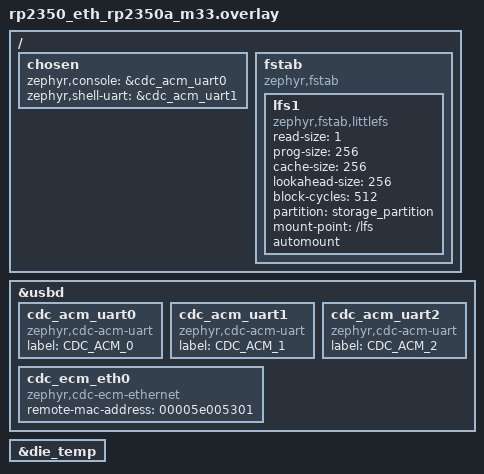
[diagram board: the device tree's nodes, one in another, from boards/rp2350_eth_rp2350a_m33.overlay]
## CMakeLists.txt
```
# SPDX-License-Identifier: Apache-2.0

cmake_minimum_required(VERSION 3.20.0)
find_package(Zephyr REQUIRED HINTS $ENV{ZEPHYR_BASE})
project(shell_module)

zephyr_library_sources(src/main.cpp)
zephyr_library_sources_ifdef(CONFIG_APP_BLINKY src/led.c)
zephyr_library_sources_ifdef(CONFIG_APP_SCPI src/scpi.cpp)
zephyr_library_sources_ifdef(CONFIG_SETTINGS src/settings.c)
zephyr_library_sources_ifdef(CONFIG_APP_ECHO_SERVER src/console_server.c)
target_sources(app PRIVATE ${app_sources}) # ${scpi_sources})

target_compile_options(
		app
		PRIVATE -Wall # All common warnings
										-Wextra # Extra warnings
										-Wpedantic # Strict ISO compliance
										-Wconversion # Implicit conversions
										-Wshadow # Variable shadowing
										-Wnon-virtual-dtor # Warn if class has virtual methods but no virtual
										# destructor
		# -Wold-style-cast   # Old-style casts (C-style)
)
```

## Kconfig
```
# Copyright (c) 2019 Nordic Semiconductor ASA
# SPDX-License-Identifier: Apache-2.0

menu "Application Configuration"
config APP_ECHO_SERVER
	bool "Enable echo telnet server"
	default n 
	help 
		Enable echo server 
	depends on NETWORKING
	depends on NET_TCP
	depends on NET_IPV4 || NET_IPV6
	select NET_SOCKETS_SERVICE
	select NET_SOCKETS

config APP_BLINKY
	bool "Enable blinky"
	select LED_STRIP
	default n
	help 
	  Use led strip blinky

if APP_BLINKY
config SAMPLE_LED_UPDATE_DELAY
	int "Delay between LED updates in ms"
	default 50
	help
	  Delay between LED updates in ms.

config SAMPLE_LED_BRIGHTNESS
	int "LED brightness"
	default 12
	range 1 255
	help
	  Brightness level of each LED. Defaults to a low value to make
	  it easier to distinguish colors.

endif

config APP_RS485 
	bool "Half duplex RS-485 serial"
	select UART_LINE_CTRL
	default n
	help 
		Enable flow control for RS-485 half duplex

config APP_SCPI
	bool "Enable SCPI Console"
	depends on CONSOLE
	depends on CONSOLE_SUBSYS
	depends on UART_CONSOLE
	depends on CONSOLE_GETCHAR
	depends on !CONSOLE_GETLINE
	default n
	help 
	  Enable scpi over console

config APP_FULL_BINDESC
	bool "Enable full bin description fields"
	select BINDESC
	select BINDESC_DEFINE
	select BINDESC_DEFINE_BUILD_TIME
	select BINDESC_BUILD_DATE_TIME_STRING
	select BINDESC_BUILD_TIME_ALWAYS_REBUILD
	select BINDESC_DEFINE_VERSION
	select BINDESC_KERNEL_VERSION_STRING
	select BINDESC_DEFINE_HOST_INFO
	select BINDESC_APP_VERSION_STRING
	select BINDESC_APP_VERSION_MAJOR
	select BINDESC_APP_VERSION_MINOR
	select BINDESC_APP_VERSION_PATCHLEVEL
	select BINDESC_APP_VERSION_NUMBER
	select BINDESC_APP_BUILD_VERSION
	select BINDESC_DEFINE_HOST_INFO
	select BINDESC_HOST_NAME
	select BINDESC_C_COMPILER_NAME
	select BINDESC_C_COMPILER_VERSION
	select BINDESC_CXX_COMPILER_NAME
	select BINDESC_CXX_COMPILER_VERSION
	default y 
	help 
		Selects all default bindesc fields 
		
endmenu

source "Kconfig.zephyr"
```

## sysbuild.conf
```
# Sysbuild configuration file.

# Enable MCUboot using overwrite only mode for this sample.
#SB_CONFIG_BOOTLOADER_NONE=y
SB_CONFIG_BOOTLOADER_MCUBOOT=y

#SB_CONFIG_MCUBOOT_SIGNATURE_KEY_FILE="bootloader/mcuboot/root-rsa-2048.pem"

SB_CONFIG_BOOT_SIGNATURE_TYPE_NONE=y
SB_CONFIG_MCUBOOT_MODE_SWAP_SCRATCH=n
SB_CONFIG_MCUBOOT_MODE_SWAP_USING_MOVE=y
SB_CONFIG_MCUBOOT_MODE_OVERWRITE_ONLY=n 
SB_CONFIG_MCUBOOT_MODE_DIRECT_XIP=n 
SB_CONFIG_MCUBOOT_MODE_DIRECT_XIP_WITH_REVERT=n 
SB_CONFIG_MCUBOOT_MODE_FIRMWARE_UPDATER=n 
SB_CONFIG_MCUBOOT_MODE_SINGLE_APP=n

# SB_CONFIG_MCUBOOT_MODE_RAM_LOAD=y
```

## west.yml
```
manifest:
  version: 0.8

  projects:
    - name: zephyr
      url: https://github.com/zephyrproject-rtos/zephyr
      revision: v4.3.0
      import:
        file: west.yml
        path-prefix: deps
        name-allowlist:
          - zephyr
          - cmsis
          - cmsis_6
          - hal_nordic
          - mcuboot
          - zcbor
          - mbedtls
          - modbus
          - hal_rpi_pico
          - littlefs
          - picolibc

    - name: scpi-parser
      url: https://github.com/snhobbs/scpi-parser
      revision: master # or a specific tag/commit
      path: deps/scpi-parser # local folder inside your Zephyr workspace

  self:
    path: app
```

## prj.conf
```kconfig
confs/prj.conf
```

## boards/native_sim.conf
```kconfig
CONFIG_STDOUT_CONSOLE=n
CONFIG_GLIBCXX_LIBCPP=n

# CONFIG_COMMON_LIBC_REMOVE=n
# CONFIG_EXTERNAL_MODULE_LIBCPP is not set
# CONFIG_CPP_EXCEPTIONS is not set
# CONFIG_CPP_RTTI is not set
#

# CONFIG_FUSE_FS_ACCESS=y

CONFIG_SYMTAB=n


CONFIG_SYMTAB_SHELL=n
CONFIG_ISR_TABLE_SHELL=n
CONFIG_PICOLIBC=n
CONFIG_MINIMAL_LIBC=n
```

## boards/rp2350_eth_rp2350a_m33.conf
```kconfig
CONFIG_APP_BLINKY=y
```

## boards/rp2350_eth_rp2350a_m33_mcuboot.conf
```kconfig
CONFIG_APP_BLINKY=y
CONFIG_SAMPLE_LED_UPDATE_DELAY=25
CONFIG_SAMPLE_LED_BRIGHTNESS=2

##################################
# MCUBOOT
##################################
CONFIG_IMG_MANAGER=y
CONFIG_IMG_ENABLE_IMAGE_CHECK=y 
CONFIG_MCUBOOT_IMG_MANAGER=y

CONFIG_MCUBOOT_SHELL=y
CONFIG_UPDATEABLE_IMAGE_NUMBER=1
CONFIG_BOOTLOADER_MCUBOOT=y
CONFIG_MCUBOOT_BOOTUTIL_LIB=y

CONFIG_FLASH=y
CONFIG_FLASH_MAP=y
CONFIG_STREAM_FLASH=y

CONFIG_RETENTION=y
CONFIG_RETENTION_BOOT_MODE=y
CONFIG_RETAINED_MEM=y
CONFIG_REBOOT=y
CONFIG_RESET=y

##################################
# MCUMGR 
##################################
CONFIG_NET_BUF=y
CONFIG_BASE64=y
CONFIG_ZCBOR=y
CONFIG_CRC=y

CONFIG_SHELL=y

CONFIG_FLASH=y
CONFIG_FLASH_MAP=y
CONFIG_STREAM_FLASH=y
CONFIG_STREAM_FLASH_PROGRESS=n
CONFIG_STREAM_FLASH_INSPECT=y
CONFIG_STREAM_FLASH_ERASE=y

# mcumgr core
CONFIG_MCUMGR=y
CONFIG_MCUMGR_GRP_SHELL=y
CONFIG_MCUMGR_TRANSPORT_SHELL=y
# CONFIG_MCUMGR_TRANSPORT_UART=y
# CONFIG_UART_MCUMGR=y
CONFIG_SHELL_BACKEND_DUMMY=y
CONFIG_MCUMGR_LOG_LEVEL_DBG=y

CONFIG_MCUMGR_GRP_IMG=y
CONFIG_MCUMGR_GRP_IMG_UPDATABLE_IMAGE_NUMBER=1
CONFIG_MCUMGR_GRP_IMG_VERBOSE_ERR=y
CONFIG_MCUMGR_GRP_IMG_ALLOW_CONFIRM_NON_ACTIVE_IMAGE_SECONDARY=y
CONFIG_MCUMGR_GRP_IMG_ALLOW_CONFIRM_NON_ACTIVE_IMAGE_ANY=y
CONFIG_MCUMGR_GRP_IMG_ALLOW_ERASE_PENDING=y
CONFIG_MCUMGR_GRP_IMG_DIRECT_UPLOAD=y
CONFIG_MCUMGR_GRP_IMG_ALLOW_CONFIRM_NON_ACTIVE_SLOT=y
# CONFIG_MCUMGR_GRP_IMG_FRUGAL_LIST is not set
CONFIG_MCUMGR_GRP_IMG_VERSION_CMP_USE_BUILD_NUMBER=y
# CONFIG_MCUMGR_GRP_IMG_MUTEX is not set
# CONFIG_MCUMGR_GRP_IMG_TOO_LARGE_DISABLED is not set
CONFIG_MCUMGR_GRP_IMG_TOO_LARGE_SYSBUILD=y
CONFIG_MCUMGR_GRP_IMG_IMAGE_SLOT_STATE_STATES=15
CONFIG_MCUMGR_GRP_IMG_SLOT_INFO=y

CONFIG_MCUMGR_GRP_OS=y
CONFIG_MCUMGR_GRP_OS_RESET_MS=250
# CONFIG_MCUMGR_GRP_OS_TASKSTAT is not set
CONFIG_MCUMGR_GRP_OS_ECHO=y
CONFIG_MCUMGR_GRP_OS_MCUMGR_PARAMS=y
CONFIG_MCUMGR_GRP_OS_INFO=y
CONFIG_MCUMGR_GRP_OS_INFO_BUILD_DATE_TIME=y
CONFIG_MCUMGR_GRP_OS_BOOTLOADER_INFO=y

CONFIG_MCUMGR_GRP_STAT=y
CONFIG_MCUMGR_GRP_ZBASIC=y
CONFIG_MCUMGR_GRP_ZBASIC_STORAGE_ERASE=y
CONFIG_MCUMGR_GRP_SETTINGS=y
CONFIG_MCUMGR_GRP_ENUM=y
```

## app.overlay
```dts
/*
 * Copyright (c) 2021 Nordic Semiconductor ASA
 *
 * SPDX-License-Identifier: Apache-2.0
 */

//#include <zephyr/dt-bindings/dma/rpi-pico-dma-rp2040.h>
//#include <zephyr/dt-bindings/dma/rpi-pico-dma-rp2350.h>
//#include <zephyr/dt-bindings/pinctrl/rpi-pico-rp2350a-pinctrl.h>

/ {
	chosen {
		zephyr,mcumgr = &cdc_acm_uart0;
		zephyr,shell-uart = &cdc_acm_uart1;
		zephyr,console = &cdc_acm_uart2;
		//zephyr,code-partition = &slot0_partition;
	};
};

&die_temp {
	status = "okay";
};



&zephyr_udc0 {
	cdc_acm_uart0: cdc_acm_uart0 {
		status = "okay";
		compatible = "zephyr,cdc-acm-uart";
		label = "CDC_ACM_0";
	};
	cdc_acm_uart1: cdc_acm_uart1 {
		status = "okay";
		compatible = "zephyr,cdc-acm-uart";
		label = "CDC_ACM_1";
	};
	cdc_acm_uart2: cdc_acm_uart2 {
		status = "okay";
		compatible = "zephyr,cdc-acm-uart";
		label = "CDC_ACM_2";
	};
};
```

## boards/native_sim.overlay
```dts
/*
 * Copyright (c) 2019 Jan Van Winkel (jan.van_winkel@dxplore.eu)
 *
 * SPDX-License-Identifier: Apache-2.0
 */

/ {
	chosen {
		zephyr,uart-mcumgr = &uart0;
		zephyr,shell-uart = &uart1;
		zephyr,console = &uart2;
	};

	uart0: uart {
		status = "okay";
		compatible = "zephyr,native-pty-uart";
		/* Dummy current-speed entry to comply with serial
		 * DTS binding
		 */
		current-speed = <115200>;
	};

	uart1: uart_1 {
		status = "okay";
		compatible = "zephyr,native-pty-uart";
		/* Dummy current-speed entry to comply with serial
		 * DTS binding
		 */
		current-speed = <0>;
	};
	uart2: uart_2 {
		status = "okay";
		compatible = "zephyr,native-pty-uart";
		/* Dummy current-speed entry to comply with serial
		 * DTS binding
		 */
		current-speed = <0>;
	};
};


/ {
	fstab {
		compatible = "zephyr,fstab";
		lfs1: lfs1 {
			compatible = "zephyr,fstab,littlefs";
			read-size = <1>;
			prog-size = <256>;
			cache-size = <256>;
			lookahead-size = <256>;
			block-cycles = <512>;
			partition = <&storage_partition>;
			mount-point = "/lfs";
			automount;
		};
	};
};
```

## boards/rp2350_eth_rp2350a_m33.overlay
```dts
#include <vendor/raspberrypi/rp2350-boot-mode-retention.dtsi>
/ {
	chosen {
		zephyr,console = &cdc_acm_uart0;
		zephyr,shell-uart = &cdc_acm_uart1;
		//zephyr,uart-mcumgr = &cdc_acm_uart2;
	};
};

zephyr_udc0: &usbd {
	//compatible = "raspberrypi,rp-usbd";
	status = "okay";
	cdc_acm_uart0: cdc_acm_uart0 {
		status = "okay";
		compatible = "zephyr,cdc-acm-uart";
		label = "CDC_ACM_0";
	};
	cdc_acm_uart1: cdc_acm_uart1 {
		status = "okay";
		compatible = "zephyr,cdc-acm-uart";
		label = "CDC_ACM_1";
	};
	cdc_acm_uart2: cdc_acm_uart2 {
		status = "okay";
		compatible = "zephyr,cdc-acm-uart";
		label = "CDC_ACM_2";
	};
	cdc_ecm_eth0: cdc_ecm_eth0 {
		compatible = "zephyr,cdc-ecm-ethernet";
		remote-mac-address = "00005e005301";
	};
};

&die_temp {
	status = "okay";
};

/ {
	fstab {
		compatible = "zephyr,fstab";
		lfs1: lfs1 {
			compatible = "zephyr,fstab,littlefs";
			read-size = <1>;
			prog-size = <256>;
			cache-size = <256>;
			lookahead-size = <256>;
			block-cycles = <512>;
			partition = <&storage_partition>;
			mount-point = "/lfs";
			automount;
		};
	};
};
```

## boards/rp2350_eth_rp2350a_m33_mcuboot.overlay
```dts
#include <vendor/raspberrypi/rp2350-boot-mode-retention.dtsi>

/ {
	chosen {
		zephyr,console = &cdc_acm_uart0;
		zephyr,shell-uart = &cdc_acm_uart1;
		zephyr,uart-mcumgr = &cdc_acm_uart2;
		zephyr,code-partition = &slot0_partition;
	};
};

zephyr_udc0: &usbd {
	//compatible = "raspberrypi,rp-usbd";
	status = "okay";
	cdc_acm_uart0: cdc_acm_uart0 {
		status = "okay";
		compatible = "zephyr,cdc-acm-uart";
		label = "CDC_ACM_0";
	};
	cdc_acm_uart1: cdc_acm_uart1 {
		status = "okay";
		compatible = "zephyr,cdc-acm-uart";
		label = "CDC_ACM_1";
	};
	cdc_acm_uart2: cdc_acm_uart2 {
		status = "okay";
		compatible = "zephyr,cdc-acm-uart";
		label = "CDC_ACM_2";
	};
};
```

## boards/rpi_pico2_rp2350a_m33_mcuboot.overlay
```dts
/ {
	chosen {
		zephyr,shell-uart = &cdc_acm_uart1;
		zephyr,console = &cdc_acm_uart2;
		zephyr,code-partition = &slot0_partition;
	};
};

zephyr_udc0: &usbd {
	//compatible = "raspberrypi,rp-usbd";
	status = "okay";
	cdc_acm_uart0: cdc_acm_uart0 {
		status = "okay";
		compatible = "zephyr,cdc-acm-uart";
		label = "CDC_ACM_0";
	};
	cdc_acm_uart1: cdc_acm_uart1 {
		status = "okay";
		compatible = "zephyr,cdc-acm-uart";
		label = "CDC_ACM_1";
	};
	cdc_acm_uart2: cdc_acm_uart2 {
		status = "okay";
		compatible = "zephyr,cdc-acm-uart";
		label = "CDC_ACM_2";
	};

};
```

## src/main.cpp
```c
/*
 * Copyright (c) 2016 Intel Corporation.
 *
 * SPDX-License-Identifier: Apache-2.0
 */

#include <zephyr/bindesc.h>

#include <zephyr/app_version.h>
#include <zephyr/console/console.h>
#include <zephyr/console/tty.h>
#include <zephyr/devicetree.h>
#include <zephyr/drivers/uart.h>
#include <zephyr/dsp/print_format.h>
#include <zephyr/kernel.h>
#include <zephyr/rtio/rtio.h>
#include <zephyr/sys/printk.h>
#include <zephyr/sys/util_macro.h>

#include <zephyr/device.h>
#include <zephyr/logging/log.h>

#include <zephyr/device.h>
#include <zephyr/drivers/gpio.h>
#include <zephyr/kernel.h>

#define WORKQ_STACK_SIZE 1024
#define WORKQ_PRIORITY K_LOWEST_APPLICATION_THREAD_PRIO

K_THREAD_STACK_DEFINE(workq_stack, WORKQ_STACK_SIZE);
static struct k_work_q workq;
#if CONFIG_APP_BLINKY
#include "led.h"
K_WORK_DEFINE(led_work, led_work_handler);

void led_timer_handler(struct k_timer *timer_id) {
  k_work_submit_to_queue(&workq, &led_work);
}

K_TIMER_DEFINE(timer, led_timer_handler, NULL);

void start_led_timer() {
  k_timer_start(&timer, K_MSEC(0), K_MSEC(CONFIG_SAMPLE_LED_UPDATE_DELAY));
}

#else
void setup_leds() {}
void led_work_handler(struct k_work *work) {}
#endif

#if CONFIG_SETTINGS
#include "settings.h"
#endif

#if CONFIG_APP_SCPI
#include "scpi.hpp"
#include <array>
#include <scpi/scpi.h>
#endif

#if CONFIG_NETWORKING
#include "console_server.h"
#endif

#define BINDESC_ID_APP_VERSION_STRING APP_VERSION

// BUILD_ASSERT(DT_NODE_HAS_COMPAT(DT_CHOSEN(zephyr_console),
// zephyr_cdc_acm_uart),
//              "Console device is not ACM CDC UART device");

/* Declare the timer */
#define LOG_LEVEL 4
#include <zephyr/logging/log.h>
LOG_MODULE_REGISTER(main);

#if CONFIG_BOOT_SERIAL_BOOT_MODE
#include <zephyr/retention/bootmode.h>
#include <zephyr/shell/shell.h>
#include <zephyr/sys/reboot.h>
static int cmd_mcuboot_serial(const struct shell *sh, size_t argc,
                              char **argv) {

  shell_print(sh, "\n");
  int rc = bootmode_set(BOOT_MODE_TYPE_BOOTLOADER);

  if (rc == 0)
    sys_reboot(SYS_REBOOT_WARM);

  return 0;
}

SHELL_CMD_REGISTER(serial_recovery, NULL, "Serial recovery",
                   cmd_mcuboot_serial);
#endif

int main(void) {
#if CONFIG_APP_BLINKY
  k_work_queue_start(&workq, workq_stack, K_THREAD_STACK_SIZEOF(workq_stack),
                     WORKQ_PRIORITY, NULL);
  start_led_timer();
#endif

#if CONFIG_APP_SCPI
  console_init();
  start_scpi_thread();
#endif

#if CONFIG_SETTINGS
  const int retval = app_settings_init();
#endif

#if APP_ECHO_SERVER
  run_server();
#endif
  return 0;
}
```

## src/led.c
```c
#include "led.h"
#include <errno.h>
#include <string.h>

#include <zephyr/device.h>
#include <zephyr/drivers/led_strip.h>
#include <zephyr/kernel.h>
#include <zephyr/sys/util.h>

#define LOG_LEVEL 4
#include <zephyr/logging/log.h>
LOG_MODULE_REGISTER(led);

#define STRIP_NODE DT_ALIAS(led_strip)

#if DT_NODE_HAS_PROP(STRIP_NODE, chain_length)
#define STRIP_NUM_PIXELS DT_PROP(STRIP_NODE, chain_length)
#else
#error Unable to determine length of LED strip
#endif

#define RGB(_r, _g, _b) {.r = (_r), .g = (_g), .b = (_b)}

static const struct led_rgb colors[] = {
    RGB(CONFIG_SAMPLE_LED_BRIGHTNESS, 0x00, 0x00), /* red */
    RGB(0x00, CONFIG_SAMPLE_LED_BRIGHTNESS, 0x00), /* green */
    RGB(0x00, 0x00, CONFIG_SAMPLE_LED_BRIGHTNESS), /* blue */
};

static struct led_rgb pixels[STRIP_NUM_PIXELS];

static const struct device *const strip = DEVICE_DT_GET(STRIP_NODE);

static size_t color = 0;

void setup_leds(void) {
  if (device_is_ready(strip)) {
    LOG_INF("Found LED strip device %s", strip->name);
  } else {
    LOG_ERR("LED strip device %s is not ready", strip->name);
  }
}

void led_work_handler(struct k_work *work) {
  ARG_UNUSED(work);
  for (size_t cursor = 0; cursor < ARRAY_SIZE(pixels); cursor++) {
    memset(&pixels, 0x00, sizeof(pixels));
    memcpy(&pixels[cursor], &colors[color], sizeof(struct led_rgb));

    const int rc = led_strip_update_rgb(strip, pixels, STRIP_NUM_PIXELS);
    if (rc) {
      LOG_ERR("couldn't update strip: %u", rc);
    }
  }

  color = (color + 1) % ARRAY_SIZE(colors);
}
```

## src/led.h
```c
#include <zephyr/kernel.h>

#ifdef __cplusplus
extern "C" {
#endif
extern void setup_leds();
extern void led_work_handler(struct k_work *work);

#ifdef __cplusplus
};
#endif
```

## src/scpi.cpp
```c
/*
 * Copyright (c) 2025 ElectroOptical Innovations. All Rights Reserved.
 * scpi.cpp
 * Structure
 * + Forward declarations
 * + Table
 * + Functions
 * */

#include "scpi.hpp"
#include <array>
#include <cstdio>
#include <iostream>
#include <limits>
#include <scpi/scpi.h>
#include <span>

static scpi_result_t SCPI_Help(scpi_t *context);

// shell_put_line(g_serial_number.data());
// shell_put_line(compile_date);
// reset();

// ---- Helper Macros ----
#define SCPI_DEF_SETTER(name, setter)                                          \
  static void setter(uint32_t) {}                                              \
  static scpi_result_t SCPI_Set_##name(scpi_t *context) {                      \
    uint32_t value;                                                            \
    if (!SCPI_ParamUInt32(context, &value, true)) {                            \
      return SCPI_RES_ERR;                                                     \
    }                                                                          \
    setter(value);                                                             \
    return SCPI_RES_OK;                                                        \
  }

#define SCPI_DEF_GETTER(name, getter)                                          \
  static uint32_t getter() { return 0; }                                       \
  static scpi_result_t SCPI_Get_##name(scpi_t *context) {                      \
    SCPI_ResultUInt32(context, getter());                                      \
    return SCPI_RES_OK;                                                        \
  }

#define SCPI_DEF_BOOL_SETTER(name, setter)                                     \
  static void setter(bool) {}                                                  \
  static scpi_result_t SCPI_Set_##name(scpi_t *context) {                      \
    bool value;                                                                \
    if (!SCPI_ParamBool(context, &value, true)) {                              \
      return SCPI_RES_ERR;                                                     \
    }                                                                          \
    setter(value);                                                             \
    return SCPI_RES_OK;                                                        \
  }

#define SCPI_DEF_BOOL_GETTER(name, getter)                                     \
  static bool getter() { return false; }                                       \
  static scpi_result_t SCPI_Get_##name(scpi_t *context) {                      \
    SCPI_ResultBool(context, getter());                                        \
    return SCPI_RES_OK;                                                        \
  }

// ---- Concrete bindings ----
SCPI_DEF_SETTER(Vbtx, set_txdac)
SCPI_DEF_GETTER(Vbtx, get_txdac)

SCPI_DEF_SETTER(Vbrx, set_rxdac)
SCPI_DEF_GETTER(Vbrx, get_rxdac)

SCPI_DEF_SETTER(Slbias, set_slbias)
SCPI_DEF_GETTER(Slbias, get_slbias)

SCPI_DEF_SETTER(Sbbias, set_sbbias)
SCPI_DEF_GETTER(Sbbias, get_sbbias)

SCPI_DEF_SETTER(Da, set_da)
SCPI_DEF_GETTER(Da, get_da)

SCPI_DEF_SETTER(Db, set_db)
SCPI_DEF_GETTER(Db, get_db)

SCPI_DEF_BOOL_SETTER(vtdr_enable, set_vtdr_enable);
SCPI_DEF_BOOL_GETTER(vtdr_enable, get_vtdr_enable);

SCPI_DEF_BOOL_SETTER(v3p6r_enable, set_v3p6r_enable);
SCPI_DEF_BOOL_GETTER(v3p6r_enable, get_v3p6r_enable);

SCPI_DEF_SETTER(npoints, set_npoints);
SCPI_DEF_GETTER(npoints, get_npoints);

SCPI_DEF_SETTER(naverages, set_naverages);
SCPI_DEF_GETTER(naverages, get_naverages);

SCPI_DEF_SETTER(istart, set_istart);
SCPI_DEF_GETTER(istart, get_istart);

SCPI_DEF_SETTER(npulses, set_npulses);
SCPI_DEF_GETTER(npulses, get_npulses);

SCPI_DEF_SETTER(a, set_a);
SCPI_DEF_GETTER(a, get_a);

SCPI_DEF_SETTER(rc, set_rc);
SCPI_DEF_GETTER(rc, get_rc);

SCPI_DEF_SETTER(b, set_b);
SCPI_DEF_GETTER(b, get_b);

SCPI_DEF_SETTER(m, set_m);
SCPI_DEF_GETTER(m, get_m);

SCPI_DEF_SETTER(spacing, set_spacing);
SCPI_DEF_GETTER(spacing, get_spacing);

SCPI_DEF_BOOL_GETTER(is_calibrated, get_is_calibrated);
SCPI_DEF_BOOL_SETTER(echo, set_echo);

SCPI_DEF_GETTER(v3p6t, get_v3p6t);
SCPI_DEF_GETTER(imon, get_imon);
SCPI_DEF_GETTER(v5p0, get_v5p0);
SCPI_DEF_GETTER(v3p6r, get_v3p6r);
SCPI_DEF_GETTER(vtemp, get_vtemp);
SCPI_DEF_GETTER(vp, get_vp);
SCPI_DEF_GETTER(vsample, get_vsample);
SCPI_DEF_GETTER(visp, get_visp);

static void set_stop(const bool stop) {}
static void set_quiet(const bool stop) {}

static scpi_result_t SCPI_Set_stop(scpi_t *context) {
  bool stop_value;
  if (!SCPI_ParamBool(context, &stop_value, true)) {
    return SCPI_RES_ERR;
  }
  set_stop(stop_value);
  bool quiet_value;
  if (SCPI_ParamBool(context, &quiet_value, false)) {
    set_quiet(quiet_value);
  }

  return SCPI_RES_OK;
}

const char *compile_date_{__DATE__};

static scpi_result_t SCPI_Get_compile_date(scpi_t *context) {
  SCPI_ResultText(context, compile_date_);
  return SCPI_RES_OK;
}

static void set_dfu() {}
static scpi_result_t SCPI_Set_dfu(scpi_t *context) {
  const constexpr std::array<scpi_choice_def_t, 2> dfu_code_{
      scpi_choice_def_t{"BEEF", 0}, SCPI_CHOICE_LIST_END};

  int32_t index = std::numeric_limits<int32_t>::max();

  const bool choice_found =
      SCPI_ParamChoice(context, dfu_code_.data(), &index, false);

  if (!choice_found) {
    return SCPI_RES_ERR;
  }
  set_dfu();
  return SCPI_RES_OK;
}

static const constexpr std::array<scpi_choice_def_t, 7>
    programmable_calibration_slots_{scpi_choice_def_t{"A1", 1},
                                    {"A2", 2},
                                    {"B1", 4},
                                    {"B2", 5},
                                    {"C1", 7},
                                    {"C2", 8},
                                    SCPI_CHOICE_LIST_END};

static const constexpr std::array<scpi_choice_def_t, 10> calibration_slots_{
    scpi_choice_def_t{"A0", 0},
    {"A1", 1},
    {"A2", 2},
    {"B0", 3},
    {"B1", 4},
    {"B2", 5},
    {"C0", 6},
    {"C1", 7},
    {"C2", 8},
    SCPI_CHOICE_LIST_END};

static scpi_result_t SCPI_Set_store_calibration(scpi_t *context) {
  int32_t value = 0;

  if (!SCPI_ParamChoice(context, programmable_calibration_slots_.data(), &value,
                        true)) {
    return SCPI_RES_ERR;
  }
  return SCPI_RES_OK;
}

static scpi_result_t SCPI_Set_recall_calibration(scpi_t *context) {
  int32_t value = 0;

  if (!SCPI_ParamChoice(context, calibration_slots_.data(), &value, true)) {
    return SCPI_RES_ERR;
  }
  return SCPI_RES_OK;
}

static scpi_result_t SCPI_Set_timing_params(scpi_t *context) {
  std::array<float, 4> values{};

  for (auto &v : values) {
    if (!SCPI_ParamFloat(context, &v, true)) {
      return SCPI_RES_ERR;
    }
  }
  set_a(values[0]);
  set_rc(values[1]);
  set_b(values[2]);
  set_m(values[3]);
  printf("%f,%f,%f,%f\n", values[0], values[1], values[2], values[3]);
  return SCPI_RES_OK;
}

static scpi_result_t SCPI_Get_timing_params(scpi_t *context) {
  std::array<float, 4> values{get_a(), get_rc(), get_b(), get_m()};

  SCPI_ResultArrayFloat(context, values.data(), values.size(),
                        scpi_array_format_t::SCPI_FORMAT_ASCII);
  return SCPI_RES_OK;
}

struct TimingParameters {
  float a = 1;
  float rc = 1;
  float b = 1;
  float m = 1;
};

struct MeasurementParameters {
  uint32_t spacing_ps = 10;
  float rc = 100;
  uint32_t npoints = 1000;
  uint32_t i_start = 100;
  TimingParameters calibration{1, 2, 3, 4};
};

static scpi_result_t SCPI_Get_rxdac_points(scpi_t *context) {
  MeasurementParameters params{};
  const auto cal = params.calibration;
  const float rc_step = cal.rc / static_cast<float>(params.spacing_ps);
  for (std::size_t i = 0; i < params.npoints; i++) {
    const float dac = 1.2345f;
    // calc_dac_point<float>(i + params.i_start, cal.a, rc_step, cal.b, cal.m);
    SCPI_ResultFloat(context, dac);
  }
  return SCPI_RES_OK;
}

#define DEF_GET_COMMAND(arg, name) {arg, SCPI_Get_##name, 0}
#define DEF_SET_COMMAND(arg, name) {arg, SCPI_Set_##name, 0}

static const scpi_command_t scpi_commands_table_[] = {
    /* IEEE Mandated Commands (SCPI std V1999.0 4.1.1) */
    scpi_command_t{"*ESE", SCPI_CoreEse, 0},
    {"*ESE?", SCPI_CoreEseQ, 0},
    {"*ESR?", SCPI_CoreEsrQ, 0},
    {"*IDN?", SCPI_CoreIdnQ, 0},
    {"*OPC", SCPI_CoreOpc, 0},
    {"*OPC?", SCPI_CoreOpcQ, 0},
    {"*RST", SCPI_CoreRst, 0},
    {"*SRE", SCPI_CoreSre, 0},
    {"*SRE?", SCPI_CoreSreQ, 0},
    {"*STB?", SCPI_CoreStbQ, 0},
    {"*TST?", SCPI_CoreTstQ, 0},
    {"*WAI", SCPI_CoreWai, 0},
    DEF_SET_COMMAND("*SAV", store_calibration),
    DEF_SET_COMMAND("*RCL", recall_calibration),
    DEF_SET_COMMAND("Echo", echo),
    DEF_SET_COMMAND("STOP", stop),
    {"HELP", SCPI_Help, 0},

    DEF_GET_COMMAND("DATE?", compile_date),
    DEF_SET_COMMAND("DFU", dfu),
    DEF_GET_COMMAND("VTDR?", v3p6t),
    DEF_GET_COMMAND("IMON?", imon),
    DEF_GET_COMMAND("V5?", v5p0),
    DEF_GET_COMMAND("VREF?", v3p6r),
    DEF_GET_COMMAND("TEMP?", vtemp),
    DEF_GET_COMMAND("VIN?", vp),
    DEF_GET_COMMAND("VSAMP?", vsample),
    DEF_GET_COMMAND("VISP?", visp),

    DEF_GET_COMMAND("MEASure:ADC:V5?", v5p0),
    DEF_GET_COMMAND("MEASure:ADC:VREF?", v3p6r),
    DEF_GET_COMMAND("MEASure:ADC:TEMP?", vtemp),
    DEF_GET_COMMAND("MEASure:ADC:VIN?", vp),
    DEF_GET_COMMAND("MEASure:ADC:VSAMP?", vsample),
    DEF_GET_COMMAND("MEASure:ADC:VISP?", visp),

    DEF_GET_COMMAND("MEASure:VOLTs:V5?", v5p0),
    DEF_GET_COMMAND("MEASure:VOLTs:VREF?", v3p6r),
    DEF_GET_COMMAND("MEASure:VOLTs:TEMP?", vtemp),
    DEF_GET_COMMAND("MEASure:VOLTs:VIN?", vp),
    DEF_GET_COMMAND("MEASure:VOLTs:VSAMP?", vsample),
    DEF_GET_COMMAND("MEASure:VOLTs:VISP?", visp),

    DEF_GET_COMMAND("MEASure:TEMPerature[:TEMP]?", vtemp),
    DEF_GET_COMMAND("MEASure:CURRent:IMON?", imon),

    DEF_SET_COMMAND("VTX", Vbtx),
    DEF_GET_COMMAND("VTX?", Vbtx),
    DEF_SET_COMMAND("VRX", Vbrx),
    DEF_GET_COMMAND("VRX?", Vbrx),
    DEF_SET_COMMAND("SLbias", Slbias),
    DEF_GET_COMMAND("SLbias?", Slbias),
    DEF_SET_COMMAND("SBbias", Sbbias),
    DEF_GET_COMMAND("SBbias?", Sbbias),
    DEF_SET_COMMAND("DA", Da),
    DEF_GET_COMMAND("DA?", Da),
    DEF_SET_COMMAND("DB", Db),
    DEF_GET_COMMAND("DB?", Db),
    DEF_SET_COMMAND("POWer[:ENable]", vtdr_enable),
    DEF_GET_COMMAND("POWer[:ENable]?", vtdr_enable),
    DEF_SET_COMMAND("VREF:ENable", v3p6r_enable),
    DEF_GET_COMMAND("VREF:ENable?", v3p6r_enable),
    DEF_SET_COMMAND("AVG", naverages),
    DEF_GET_COMMAND("AVG?", naverages),
    DEF_SET_COMMAND("PULSES", npulses),
    DEF_GET_COMMAND("PULSES?", npulses),

    DEF_SET_COMMAND("ISTART", istart),
    DEF_GET_COMMAND("ISTART?", istart),
    DEF_SET_COMMAND("RESolution", spacing),
    DEF_GET_COMMAND("RESolution?", spacing),
    DEF_SET_COMMAND("POINTS", npoints),
    DEF_GET_COMMAND("POINTS?", npoints),
    DEF_GET_COMMAND("CALibrated?", is_calibrated),
    DEF_GET_COMMAND("TIMing:CALibrated?", is_calibrated),
    DEF_SET_COMMAND("TIMing:ISTART", istart),
    DEF_GET_COMMAND("TIMing:ISTART?", istart),
    DEF_SET_COMMAND("TIMing:RESolution", spacing),
    DEF_GET_COMMAND("TIMing:RESolution?", spacing),
    DEF_SET_COMMAND("TIMing:POINTS", npoints),
    DEF_GET_COMMAND("TIMing:POINTS?", npoints),
    DEF_SET_COMMAND("TIMing:Amplitude", a),
    DEF_GET_COMMAND("TIMing:Amplitude?", a),
    DEF_SET_COMMAND("TIMing", timing_params),
    DEF_GET_COMMAND("TIMing?", timing_params),
    DEF_SET_COMMAND("TIMing:RC", rc),
    DEF_GET_COMMAND("TIMing:RC?", rc),
    DEF_SET_COMMAND("TIMing:B", b),
    DEF_GET_COMMAND("TIMing:B?", b),
    DEF_SET_COMMAND("TIMing:M", m),
    DEF_GET_COMMAND("TIMing:M?", m),
    DEF_GET_COMMAND("TIMing:RXdac?", rxdac_points),
    DEF_GET_COMMAND("RXdac?", rxdac_points),
    {nullptr, nullptr, 0}};

const std::span<const scpi_command_t> scpi_commands_table{
    scpi_commands_table_,
    sizeof(scpi_commands_table_) / sizeof(scpi_commands_table_[0])};

static scpi_result_t SCPI_Help(scpi_t *context) {
  // const char intro[] = "Available Functions:";
  // context->interface->write(context, intro, strlen(intro));
  for (const auto &cmd : scpi_commands_table) {
    if (cmd.pattern) {
      SCPI_ResultText(context, cmd.pattern);
    }
  }

  context->interface->write(context, "\r\n", 2);
  return SCPI_RES_OK;
}






#include <zephyr/console/console.h>
#include <zephyr/app_version.h>


static std::array<uint8_t, 256> scpi_input_buffer{};
static std::array<scpi_error_t, 8> scpi_error_buffer{};
static size_t SCPI_Write(scpi_t *context, const char *data, size_t len) {
  /*
   * uart or tcp output
   */
  // std::array<char, 1024> buff{};
  // snprintf(buff.data(), buff.size(), "%s", data);
  console_write(NULL, data, len);
  // printk("%s", data);
  // printk("\r\n%s", data);
  return SCPI_RES_OK;
}

static int SCPI_Error(scpi_t *context, int_fast16_t err) {
  std::array<char, 32> buff{};
  snprintf(buff.data(), buff.size(), "SCPI Error: %d\r\n", err);
  console_write(NULL, buff.data(), buff.size());
  return SCPI_RES_OK;
}

static scpi_result_t SCPI_Control(scpi_t *context, scpi_ctrl_name_t ctrl,
                                  scpi_reg_val_t val) {

  std::array<char, 32> buff{};
  snprintf(buff.data(), buff.size(), "SCPI Control: %d\r\n", val);
  console_write(NULL, buff.data(), buff.size());
  return SCPI_RES_OK;
}

static scpi_result_t SCPI_Reset(scpi_t *context) { return SCPI_RES_OK; }
static scpi_result_t SCPI_Flush(scpi_t *context) { return SCPI_RES_OK; }

K_THREAD_STACK_DEFINE(scpi_stack, 512);
struct k_thread scpi_thread_data;

#define BOARD_IDENTITY CONFIG_BOARD CONFIG_BOARD_REVISION
static ScpiInterfaceContainer scpi_interface(
    {"Hobbs ElectroOptics", BOARD_IDENTITY, APP_VERSION_EXTENDED_STRING, ""},
    {scpi_commands_table.data(), scpi_commands_table.size()},
    {scpi_input_buffer.data(), scpi_input_buffer.size()},
    {scpi_error_buffer.data(), scpi_error_buffer.size()},
    {SCPI_Error, SCPI_Write, SCPI_Control, SCPI_Flush, SCPI_Reset});

static void scpi_input_thread(void *arg1, void *arg2, void *arg3) {
  ARG_UNUSED(arg1);
  ARG_UNUSED(arg2);
  ARG_UNUSED(arg3);

  while (true) {
    const auto value = console_getchar();
    if (value >= 0) {
	  const char ch = static_cast<char>(value);
	  scpi_interface.input(&ch, 1);
	} else {
      k_sleep(K_MSEC(1));
	}
  }
}

void start_scpi_thread() {
  k_thread_create(&scpi_thread_data, scpi_stack,
                  K_THREAD_STACK_SIZEOF(scpi_stack), scpi_input_thread, NULL,
                  NULL, NULL, K_LOWEST_APPLICATION_THREAD_PRIO, 0, K_NO_WAIT);
}
```

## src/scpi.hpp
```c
#pragma once

#include "scpi/scpi.h"
#include <array>
#include <span>

const std::size_t kIdnLength = 4;
struct ScpiInterfaceContainer {
  /*
   * Container for an SCPI instance.
   * This is exclusively intended to contain the
   * */
public:
  std::array<const char *, kIdnLength> idn_fields_;
  std::span<const scpi_command_t> scpi_commands_;
  std::span<uint8_t> scpi_input_buffer_;
  std::span<scpi_error_t> scpi_error_queue_data_;
  scpi_interface_t scpi_interface_;
  scpi_t scpi_context_{};

  ScpiInterfaceContainer(const std::array<const char *, kIdnLength> idn,
                         const std::span<const scpi_command_t> command_table,
                         std::span<uint8_t> scpi_input_buffer,
                         std::span<scpi_error_t> scpi_error_queue_data,
                         const scpi_interface_t &scpi_interface)
      : idn_fields_{idn}, scpi_commands_{command_table},
        scpi_input_buffer_{scpi_input_buffer},
        scpi_error_queue_data_{scpi_error_queue_data},
        scpi_interface_{scpi_interface} {
    init();
  }

  void init() {
    /*
     * Note: scpi_units_def defined off the standard in scpi/units.c
     * */
    SCPI_Init(
        &scpi_context_,
        reinterpret_cast<const scpi_command_t *const>(scpi_commands_.data()),
        &scpi_interface_, scpi_units_def, idn_fields_.at(0), idn_fields_.at(1),
        idn_fields_.at(2), idn_fields_.at(3),
        reinterpret_cast<char *>(scpi_input_buffer_.data()),
        scpi_input_buffer_.size(),
        reinterpret_cast<scpi_error_t *>(scpi_error_queue_data_.data()),
        scpi_error_queue_data_.size());
  }

  scpi_bool_t  input(const char *str, const std::size_t size) {
    return SCPI_Input(&scpi_context_, str, size);
  }
};

extern const std::span<const scpi_command_t> scpi_commands_table;


extern void start_scpi_thread();
```

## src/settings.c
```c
/*
 * Generic Zephyr settings module
 *
 * SPDX-License-Identifier: Apache-2.0
 */

#include <errno.h>
#include <string.h>
#include <zephyr/kernel.h>
#include <zephyr/settings/settings.h>
#include <zephyr/sys/printk.h>

#if defined(CONFIG_SETTINGS_FILE)
#include <zephyr/fs/fs.h>
#include <zephyr/fs/littlefs.h>
#include <zephyr/storage/flash_map.h>
#endif

/* =========================
 * Configuration
 * ========================= */

#define SETTINGS_ROOT_NAME "app"

/* =========================
 * Stored values (defaults)
 * ========================= */

uint32_t app_counter = 0;
int32_t app_offset = 0;
char app_name[16] = "default";

/* =========================
 * Settings handler
 * ========================= */

static int app_settings_set(const char *name, size_t len,
                            settings_read_cb read_cb, void *cb_arg) {
  const char *next;
  int rc;

  if (settings_name_steq(name, "counter", &next) && !next) {
    if (len != sizeof(app_counter)) {
      return -EINVAL;
    }
    return read_cb(cb_arg, &app_counter, sizeof(app_counter));
  }

  if (settings_name_steq(name, "offset", &next) && !next) {
    if (len != sizeof(app_offset)) {
      return -EINVAL;
    }
    return read_cb(cb_arg, &app_offset, sizeof(app_offset));
  }

  if (settings_name_steq(name, "name", &next) && !next) {
    if (len >= sizeof(app_name)) {
      return -EINVAL;
    }
    rc = read_cb(cb_arg, app_name, sizeof(app_name));
    if (rc > 0) {
      app_name[rc - 1] = '\0';
    }
    return rc;
  }

  return -ENOENT;
}

static int app_settings_commit(void) {
  /* Called after all settings are loaded */
  printk("Settings loaded: counter=%u offset=%d name=%s\n", app_counter,
         app_offset, app_name);
  return 0;
}

static int app_settings_export(int (*cb)(const char *name, const void *value,
                                         size_t len)) {
  cb("app/counter", &app_counter, sizeof(app_counter));
  cb("app/offset", &app_offset, sizeof(app_offset));
  cb("app/name", app_name, strlen(app_name) + 1);
  return 0;
}

static struct settings_handler app_settings = {
    .name = SETTINGS_ROOT_NAME,
    .h_set = app_settings_set,
    .h_commit = app_settings_commit,
    .h_export = app_settings_export,
};

/* =========================
 * Initialization
 * ========================= */

int app_settings_init(void) {
  int rc;

#if defined(CONFIG_SETTINGS_FILE)
  static struct fs_mount_t fs_mnt;
  static struct fs_littlefs fs;

  fs_mnt.type = FS_LITTLEFS;
  fs_mnt.fs_data = &fs;
  fs_mnt.storage_dev = (void *)FIXED_PARTITION_ID(storage_partition);
  fs_mnt.mnt_point = "/settings";

  rc = fs_mount(&fs_mnt);
  if (rc < 0) {
    printk("Failed to mount settings FS (%d)\n", rc);
    return rc;
  }
#endif

  rc = settings_subsys_init();
  if (rc) {
    printk("settings init failed (%d)\n", rc);
    return rc;
  }

  rc = settings_register(&app_settings);
  if (rc) {
    printk("settings register failed (%d)\n", rc);
    return rc;
  }

  settings_load();
  return 0;
}
```

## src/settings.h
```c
#ifdef __cplusplus
extern "C"
{
#endif
int app_settings_init(void);

#ifdef __cplusplus
}
#endif
```
